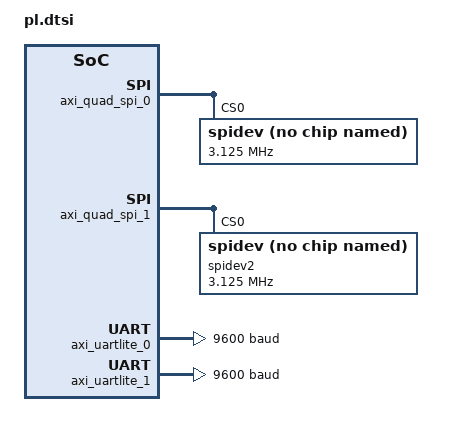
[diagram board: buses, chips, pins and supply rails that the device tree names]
/*
 * CAUTION: This file is automatically generated by Xilinx.
 * Version: HSI 2017.4
 * Today is: Wed Sep 26 11:00:42 2018
 */


/ {
	amba_pl: amba_pl {
		#address-cells = <1>;
		#size-cells = <1>;
		compatible = "simple-bus";
		ranges ;
		axi_gpio_0: gpio@41200000 {
			#gpio-cells = <3>;
			clock-names = "s_axi_aclk";
			clocks = <&clkc 15>;
			compatible = "xlnx,xps-gpio-1.00.a";
			gpio-controller ;
			reg = <0x41200000 0x10000>;
			xlnx,all-inputs = <0x0>;
			xlnx,all-inputs-2 = <0x0>;
			xlnx,all-outputs = <0x0>;
			xlnx,all-outputs-2 = <0x0>;
			xlnx,dout-default = <0x00000000>;
			xlnx,dout-default-2 = <0x00000000>;
			xlnx,gpio-width = <0x4>;
			xlnx,gpio2-width = <0x4>;
			xlnx,interrupt-present = <0x0>;
			xlnx,is-dual = <0x1>;
			xlnx,tri-default = <0xFFFFFFFF>;
			xlnx,tri-default-2 = <0xFFFFFFFF>;
		};
		axi_gpio_1: gpio@41210000 {
			#gpio-cells = <3>;
			clock-names = "s_axi_aclk";
			clocks = <&clkc 15>;
			compatible = "xlnx,xps-gpio-1.00.a";
			gpio-controller ;
			reg = <0x41210000 0x10000>;
			xlnx,all-inputs = <0x0>;
			xlnx,all-inputs-2 = <0x0>;
			xlnx,all-outputs = <0x0>;
			xlnx,all-outputs-2 = <0x0>;
			xlnx,dout-default = <0x00000000>;
			xlnx,dout-default-2 = <0x00000000>;
			xlnx,gpio-width = <0x4>;
			xlnx,gpio2-width = <0x20>;
			xlnx,interrupt-present = <0x0>;
			xlnx,is-dual = <0x0>;
			xlnx,tri-default = <0xFFFFFFFF>;
			xlnx,tri-default-2 = <0xFFFFFFFF>;
		};
		axi_quad_spi_0: axi_quad_spi@41e00000 {
			bits-per-word = <8>;
			compatible = "xlnx,xps-spi-2.00.a";
			fifo-size = <16>;
			interrupt-names = "ip2intc_irpt";
			interrupt-parent = <&intc>;
			interrupts = <0 31 1>;
			num-cs = <0x1>;
			reg = <0x41e00000 0x10000>;
			xlnx,num-ss-bits = <0x1>;
			xlnx,spi-mode = <0>;

			spidev:spidev@0{
			 compatible = "spidev";
			 reg = <0>; //chip select 0
			 spi-max-frequency = <3125000>;
			};
		};
		axi_quad_spi_1: axi_quad_spi@41e10000 {
			bits-per-word = <8>;
			compatible = "xlnx,xps-spi-2.00.a";
			fifo-size = <16>;
			interrupt-names = "ip2intc_irpt";
			interrupt-parent = <&intc>;
			interrupts = <0 32 1>;
			num-cs = <0x1>;
			reg = <0x41e10000 0x10000>;
			xlnx,num-ss-bits = <0x1>;
			xlnx,spi-mode = <0>;

			spidev2:spidev2@0{
			 compatible = "spidev";
			 reg = <0>; //chip select 0
			 spi-max-frequency = <3125000>;
			};
		};
		axi_uartlite_0: serial@42c00000 {
			clock-names = "s_axi_aclk";
			clocks = <&clkc 15>;
			compatible = "xlnx,xps-uartlite-1.00.a";
			current-speed = <9600>;
			device_type = "serial";
			interrupt-names = "interrupt";
			interrupt-parent = <&intc>;
			interrupts = <0 29 1>;
			port-number = <0>;
			reg = <0x42c00000 0x10000>;
			xlnx,baudrate = <0x2580>;
			xlnx,data-bits = <0x8>;
			xlnx,odd-parity = <0x0>;
			xlnx,s-axi-aclk-freq-hz-d = "50.0";
			xlnx,use-parity = <0x0>;
		};
		axi_uartlite_1: serial@42c10000 {
			clock-names = "s_axi_aclk";
			clocks = <&clkc 15>;
			compatible = "xlnx,xps-uartlite-1.00.a";
			current-speed = <9600>;
			device_type = "serial";
			interrupt-names = "interrupt";
			interrupt-parent = <&intc>;
			interrupts = <0 30 1>;
			port-number = <1>;
			reg = <0x42c10000 0x10000>;
			xlnx,baudrate = <0x2580>;
			xlnx,data-bits = <0x8>;
			xlnx,odd-parity = <0x0>;
			xlnx,s-axi-aclk-freq-hz-d = "50.0";
			xlnx,use-parity = <0x0>;
		};
	};
};
